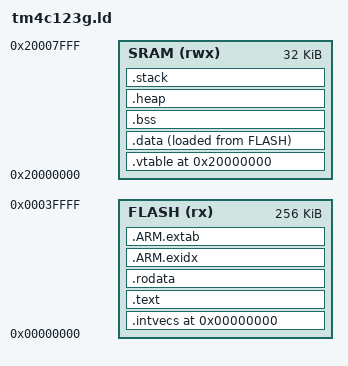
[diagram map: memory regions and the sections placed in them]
/*** Linker configuration file ***/

MEMORY
{
    /* 256KB Flash */
    FLASH (rx) : ORIGIN = 0x00000000, LENGTH = 0x00040000
    /* 32KB SRAM */
    SRAM (rwx) : ORIGIN = 0x20000000, LENGTH = 0x00008000
}

REGION_ALIAS("REGION_TEXT", FLASH);
REGION_ALIAS("REGION_ARM_EXIDX", FLASH);
REGION_ALIAS("REGION_ARM_EXTAB", FLASH);

REGION_ALIAS("REGION_BSS", SRAM);
REGION_ALIAS("REGION_DATA", SRAM);
REGION_ALIAS("REGION_STACK", SRAM);
REGION_ALIAS("REGION_HEAP", SRAM);

ENTRY(ResetISR)

SECTIONS {

    PROVIDE (_intvecs_base_address = 0x0);

    .intvecs (_intvecs_base_address) : AT (_intvecs_base_address) {
        KEEP (*(.intvecs))
    } > REGION_TEXT

    PROVIDE (_vtable_base_address = 0x20000000);

    .vtable (_vtable_base_address) : AT (_vtable_base_address) {
        KEEP (*(.vtable))
    } > REGION_DATA

    .text : {
        CREATE_OBJECT_SYMBOLS
        *(.text)
        *(.text.*)
        . = ALIGN(0x4);
        KEEP (*(.ctors))
        . = ALIGN(0x4);
        KEEP (*(.dtors))
        . = ALIGN(0x4);
        __init_array_start = .;
        KEEP (*(.init_array*))
        __init_array_end = .;
        *(.init)
        *(.fini*)
    } > REGION_TEXT

    PROVIDE (__etext = .);
    PROVIDE (_etext = .);
    PROVIDE (etext = .);

    .rodata : {
        *(.rodata)
        *(.rodata*)
    } > REGION_TEXT

    .data : ALIGN (4) {
        __data_load__ = LOADADDR (.data);
        __data_start__ = .;
        *(.data)
        *(.data*)
        . = ALIGN (4);
        __data_end__ = .;
    } > REGION_DATA AT> REGION_TEXT

    .ARM.exidx : {
        __exidx_start = .;
        *(.ARM.exidx* .gnu.linkonce.armexidx.*)
        __exidx_end = .;
    } > REGION_ARM_EXIDX

    .ARM.extab : {
        *(.ARM.extab* .gnu.linkonce.armextab.*)
    } > REGION_ARM_EXTAB

    .bss : {
        __bss_start__ = .;
        *(.shbss)
        *(.bss)
        *(.bss.*)
        *(COMMON)
        . = ALIGN (4);
        __bss_end__ = .;
    } > REGION_BSS

    .heap : {
        __heap_start__ = .;
        end = __heap_start__;
        _end = end;
        __end = end;
        . = . + HEAPSIZE;
        KEEP(*(.heap))
        __heap_end__ = .;
        __HeapLimit = __heap_end__;
    } > REGION_HEAP

    .stack : ALIGN(0x8) {
        _stack = .;
        __stack = .;
        . = . + STACKSIZE;
        __StackTop = . ;
        KEEP(*(.stack))
    } > REGION_STACK
}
